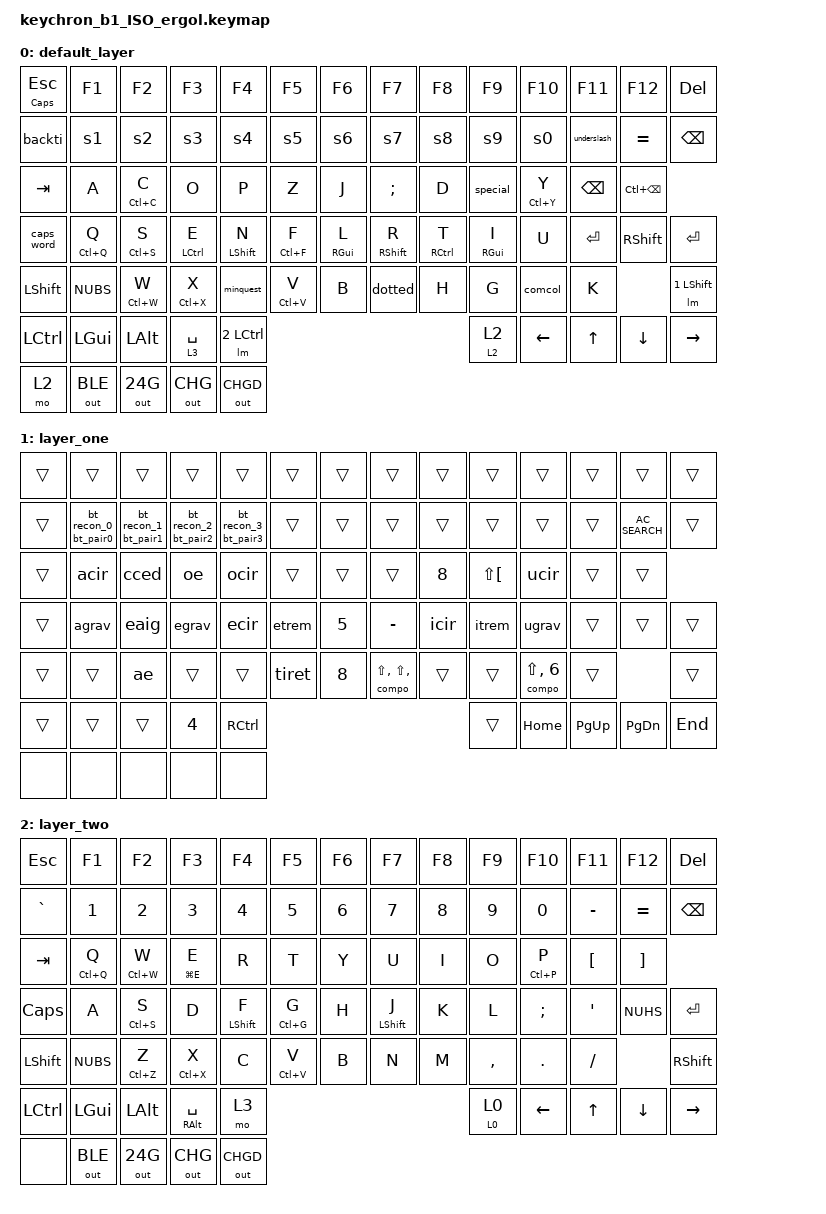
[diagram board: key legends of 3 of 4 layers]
/*
 * Copyright (c) 2023 The ZMK Contributors
 *
 * SPDX-License-Identifier: MIT
 */

#include <behaviors.dtsi>
#include <dt-bindings/zmk/keys.h>
#include <dt-bindings/zmk/rgb.h>
#include <dt-bindings/zmk/bt.h>
#include <dt-bindings/zmk/outputs.h>

&caps_word {
    continue-list = <UNDERSCORE MINUS BACKSPACE DELETE SEMI>;
};
&mt {
    tapping-term-ms = <300>;
    flavor = "tap-preferred";
};
&sl {
    release-after-ms = <5000>;
};

/ {
    ZMK_MACRO(recover, bindings = <&out OUT_RECOVER>;)
    ZMK_MACRO(change, bindings = <&out OUT_FN>;)
    ZMK_MACRO(fn_win, bindings = <&out OUT_FN_WIN>;)

    ZMK_MACRO(en_bootloader, bindings = <&bootloader>;)
    ZMK_MACRO1(MA,bindings=<&kp 0x770000>;)

    long_press_recover:l1 {
        compatible = "zmk,behavior-hold-tap";
        label = "l1";
        #binding-cells = <2>;
        flavor = "tap-preferred";
        tapping-term-ms = <3000>;  // delay amount in ms
        bindings = <&recover>, <&none>;
    };

    long_press_change:l2{
        compatible = "zmk,behavior-hold-tap";
        label = "lp_change";
        #binding-cells = <2>;
        flavor = "tap-preferred";
        tapping-term-ms = <3000>;  // delay amount in ms
        bindings = <&change>, <&none>;
    };
    long_press_bootloader:l3{
        compatible = "zmk,behavior-hold-tap";
        label = "lp_bootloader";
        #binding-cells = <2>;
        flavor = "tap-preferred";
        tapping-term-ms = <3000>;  // delay amount in ms
        bindings = <&en_bootloader>, <&none>;
    };
    long_press_fn_win:l4{
        compatible = "zmk,behavior-hold-tap";
        label = "lp_fn_win";
        #binding-cells = <2>;
        flavor = "tap-preferred";
        tapping-term-ms = <3000>;   
        bindings = <&fn_win>, <&none>;
    };
   

    combos1 {
        compatible = "zmk,combos";
        combo_jz {
            timeout-ms = <1000>;
            layers = <1 3>;
            key-positions = <48 57>; //fn+j+z
            bindings = <&long_press_recover 0 0>;
        };
        combo_xl {
            timeout-ms = <1000>;
            layers =< 1 3>;
            key-positions = <58 50>; //fn+x+l
            bindings = <&long_press_change 0 0>;
        };
        // combo_b {
        //     timeout-ms = <1000>;
        //     layers =< 1 3>;
        //     //slow-release = <true>;
        //     key-positions = <61>; //fn+b
        //     bindings = <&out OUT_BAT>;
        // };

        // combo_win_l {
        //     timeout-ms = <1000>;
        //     layers =< 1 3>;
        //     //slow-release = <true>;
        //     key-positions = <69>; //fn+win
        //     bindings = <&long_press_fn_win 0 0>;
        // };

        // combo_t0 {
        //     timeout-ms = <10 >;
        //     layers =<4>;
          
        //     key-positions = <80 90>;  
        //     bindings = <&to 3 >;
        // };
        // combo_t1 {
        //     timeout-ms = <10 >;
        //     layers =<4>;
          
        //     key-positions = <80 91>;  
        //     bindings = <&tog 3 >;
        // };
        // combo_t2 {
        //     timeout-ms = <10 >;
        //     layers =<4>;
          
        //     key-positions = <80 92>;  
        //     bindings = <&sl 3 >;
        // };
        // combo_t3 {
        //     timeout-ms = <10 >;
        //     layers =<4>;
          
        //     key-positions = <70 93>;  
        //     bindings = <&lt 3 SPACE>;
        // };
        // combo_t4 {
        //     timeout-ms = <10 >;
        //     layers =<4>;
          
        //     key-positions = <81 94>;  
        //     bindings = <&sk LSHIFT>;
        // };
        // combo_t5 {
        //     timeout-ms = <10 >;
        //     layers =<4>;
          
        //     key-positions = <81 93>;  
        //     bindings = <&mt LSHIFT SPACE>;
        // };
        // combo_t6 {
        //     timeout-ms = <10 >;
        //     layers =<4>;
          
        //     key-positions = <81 93>;  
        //     bindings = <&gresc>;
        // };
    };

    td0 {
        compatible = "zmk,behavior-tap-dance";
        label = "TAPD_LAYER";
        #binding-cells = <1>;
        tapping-term-ms = <350>;
        bindings =<&mo 0>,<&mo 0>,<&mo 0>,<&mo 0>,<&to 0>;
    };
    ZMK_MACRO(bt_pair0, bindings = <&bt BT_PAIR 0>;)
    ZMK_MACRO(bt_pair1, bindings = <&bt BT_PAIR 1>;)
    ZMK_MACRO(bt_pair2, bindings = <&bt BT_PAIR 2>;)
    ZMK_MACRO(bt_pair3, bindings = <&bt BT_PAIR 3>;)
    ZMK_MACRO(bt_recon_0, bindings = <&bt BT_SEL 0>;)
    ZMK_MACRO(bt_recon_1, bindings = <&bt BT_SEL 1>;)
    ZMK_MACRO(bt_recon_2, bindings = <&bt BT_SEL 2>;)
    ZMK_MACRO(bt_recon_3, bindings = <&bt BT_SEL 3>;)
    


    bt_pair_0: bt_pair_0 {
        compatible = "zmk,behavior-hold-tap";
        label = "bt_pair0";
        #binding-cells = <2>;
        flavor = "tap-preferred";
        tapping-term-ms = <3000>;  // delay amount in ms
        bindings = <&bt_pair0>, <&bt_recon_0>;
    };
    bt_pair_1: bt_pair_1 {
        compatible = "zmk,behavior-hold-tap";
        label = "bt_pair1";
        #binding-cells = <2>;
        flavor = "tap-preferred";
        tapping-term-ms = <3000>;  // delay amount in ms
        bindings = <&bt_pair1>, <&bt_recon_1>;
    };
    bt_pair_2: bt_pair_2 {
        compatible = "zmk,behavior-hold-tap";
        label = "bt_pair2";
        #binding-cells = <2>;
        flavor = "tap-preferred";
        tapping-term-ms = <3000>;  // delay amount in ms
        bindings = <&bt_pair2>, <&bt_recon_2>;
    };
    bt_pair_3: bt_pair_3 {
        compatible = "zmk,behavior-hold-tap";
        label = "bt_pair3";
        #binding-cells = <2>;
        flavor = "tap-preferred";
        tapping-term-ms = <3000>;  // delay amount in ms
        bindings = <&bt_pair3>, <&bt_recon_3>;
    };
    uc:user_custom {
        compatible = "zmk,behavior-key-press";
        label ="user_custom";
        #binding-cells =<1>;
    };

    // ----------------------ERGOL SPECIFICS----------------------------------
    
    behaviors {

    //LAYER 0
        minquest: minus_question {
            compatible = "zmk,behavior-mod-morph";
            #binding-cells = <0>;
            label = "- ?";
            bindings = <&kp N6>, <&kp M>;
            mods = <(MOD_LSFT|MOD_RSFT)>;
            keep-mods = <(MOD_LSFT|MOD_RSFT)>;
        };
        dotted: dot_column {
            compatible = "zmk,behavior-mod-morph";
            #binding-cells = <0>;
            label = ". :";
            bindings = <&kp LS(COMMA)>, <&kp DOT>;
            mods = <(MOD_LSFT|MOD_RSFT)>;
        };
        comcol: comma_column {
            compatible = "zmk,behavior-mod-morph";
            #binding-cells = <0>;
            label = ", ;";
            bindings = <&kp M>, <&kp COMMA>;
            mods = <(MOD_LSFT|MOD_RSFT)>;
        };
        quotted: quote_double {
            compatible = "zmk,behavior-mod-morph";
            #binding-cells = <0>;
            label = "none";
            bindings = <&kp N4>, <&kp N3>;
            mods = <(MOD_LSFT|MOD_RSFT)>;
        };
        backti: backquote_tilde {
            compatible = "zmk,behavior-mod-morph";
            #binding-cells = <0>;
            label = "tilde";
            bindings = <&kp RA(N7)>, <&kp RA(N2)>;
            mods = <(MOD_LSFT|MOD_RSFT)>;
        };
        underslash: underscore_slash {
            compatible = "zmk,behavior-mod-morph";
            #binding-cells = <0>;
            label = "slash";
            bindings = <&kp LS(DOT)>, <&kp N8>;
            mods = <(MOD_LSFT|MOD_RSFT)>;
        };
        special: special {
            compatible = "zmk,behavior-mod-morph";
            #binding-cells = <0>;
            label = "special";
            bindings = <&sl 1>, <&kp FSLH>;
            mods = <(MOD_LSFT|MOD_RSFT)>;
        };
        open: opening_brackets {
            compatible = "zmk,behavior-mod-morph";
            #binding-cells = <0>;
            label = "opening";
            bindings = <&kp RA(N5)>, <&kp RA(N4)>;
            mods = <(MOD_LSFT|MOD_RSFT)>;
        };        
        close: closing_brackets {
            compatible = "zmk,behavior-mod-morph";
            #binding-cells = <0>;
            label = "closing";
            bindings = <&kp RA(MINUS)>, <&kp RA(EQUAL)>;
            mods = <(MOD_LSFT|MOD_RSFT)>;
        };
        backpipe: backslash_pipe {
            compatible = "zmk,behavior-mod-morph";
            #binding-cells = <0>;
            label = "backpipe";
            bindings = <&kp RA(N8)>, <&kp RA(N6)>;
            mods = <(MOD_LSFT|MOD_RSFT)>;
        };

        s1: special1 {
            compatible = "zmk,behavior-mod-morph";
            #binding-cells = <0>;
            label = "1";
            bindings = <&kp LS(N1)>, <&kp RA(E)>;
            mods = <(MOD_LSFT|MOD_RSFT)>;
        };
        s2: special2 {
            compatible = "zmk,behavior-mod-morph";
            #binding-cells = <0>;
            label = "2";
            bindings = <&kp LS(N2)>, <&compo NUBS NUBS>;
            mods = <(MOD_LSFT|MOD_RSFT)>;
        };
        s3: special3 {
            compatible = "zmk,behavior-mod-morph";
            #binding-cells = <0>;
            label = "3";
            bindings = <&kp LS(N3)>, <&compo LS(NUBS) LS(NUBS)>;
            mods = <(MOD_LSFT|MOD_RSFT)>;
        };
        s4: special4 {
            compatible = "zmk,behavior-mod-morph";
            #binding-cells = <0>;
            label = "4";
            bindings = <&kp LS(N4)>, <&kp RBKT>;
            mods = <(MOD_LSFT|MOD_RSFT)>;
        };
        s5: special5 {
            compatible = "zmk,behavior-mod-morph";
            #binding-cells = <0>;
            label = "5";
            bindings = <&kp LS(N5)>, <&kp LS(SQT)>;
            mods = <(MOD_LSFT|MOD_RSFT)>;
        };
        s6: special6 {
            compatible = "zmk,behavior-mod-morph";
            #binding-cells = <0>;
            label = "6";
            bindings = <&kp LS(N6)>, <&kp LBKT>;
            mods = <(MOD_LSFT|MOD_RSFT)>;
        };     
        s7: special7 {
            compatible = "zmk,behavior-mod-morph";
            #binding-cells = <0>;
            label = "7";
            bindings = <&kp LS(N7)>, <&kp N1>;
            mods = <(MOD_LSFT|MOD_RSFT)>;
        };    
        s8: special8 {
            compatible = "zmk,behavior-mod-morph";
            #binding-cells = <0>;
            label = "8";
            bindings = <&kp LS(N8)>, <&kp NUHS>;
            mods = <(MOD_LSFT|MOD_RSFT)>;
        };            
        s9: special9 {
            compatible = "zmk,behavior-mod-morph";
            #binding-cells = <0>;
            label = "9";
            bindings = <&kp LS(N9)>, <&kp RA(N3)>;
            mods = <(MOD_LSFT|MOD_RSFT)>;
        }; 
        s0: special0 {
            compatible = "zmk,behavior-mod-morph";
            #binding-cells = <0>;
            label = "0";
            bindings = <&kp LS(N0)>, <&kp RA(N0)>;
            mods = <(MOD_LSFT|MOD_RSFT)>;
        };
        
    //LAYER1

        acir: circum_a {
            compatible = "zmk,behavior-mod-morph";
            #binding-cells = <0>;
            label = "â";
            bindings = <&dead LBKT Q>, <&dead LBKT LS(Q)>;
            mods = <(MOD_LSFT|MOD_RSFT)>;
        };

        cced: cedil_c {
            compatible = "zmk,behavior-mod-morph";
            #binding-cells = <0>;
            label = "ç";
            bindings = <&kp N9>, <&compo M LS(C)>;
            mods = <(MOD_LSFT|MOD_RSFT)>;
        };
        oe: oe {
            compatible = "zmk,behavior-mod-morph";
            #binding-cells = <0>;
            label = "œ";
            bindings = <&compo O E>, <&compo LS(O) LS(E)>;
            mods = <(MOD_LSFT|MOD_RSFT)>;
        };
        ocir: circum_o {
            compatible = "zmk,behavior-mod-morph";
            #binding-cells = <0>;
            label = "ô";
            bindings = <&dead LBKT O>, <&dead LBKT LS(O)>;
            mods = <(MOD_LSFT|MOD_RSFT)>;
        };
        ucir: circum_u {
            compatible = "zmk,behavior-mod-morph";
            #binding-cells = <0>;
            label = "û";
            bindings = <&dead LBKT U>, <&dead LBKT LS(U)>;
            mods = <(MOD_LSFT|MOD_RSFT)>;
        };
        agrav: grav_a {
            compatible = "zmk,behavior-mod-morph";
            #binding-cells = <0>;
            label = "à";
            bindings = <&kp N0>, <&compo LS(Q) RA(N7)>;
            mods = <(MOD_LSFT|MOD_RSFT)>;
        };
        eaig: aig_e {
            compatible = "zmk,behavior-mod-morph";
            #binding-cells = <0>;
            label = "é";
            bindings = <&kp N2>, <&compo LS(E) N4>;
            mods = <(MOD_LSFT|MOD_RSFT)>;
        };

        egrav: grav_e {
            compatible = "zmk,behavior-mod-morph";
            #binding-cells = <0>;
            label = "è";
            bindings = <&kp N7>, <&compo LS(E) RA(N7)>;
            mods = <(MOD_LSFT|MOD_RSFT)>;
        };
        ecir: circum_e {
            compatible = "zmk,behavior-mod-morph";
            #binding-cells = <0>;
            label = "ê";
            bindings = <&dead LBKT E>, <&dead LBKT LS(E)>;
            mods = <(MOD_LSFT|MOD_RSFT)>;
        };
        etrem: trema_e {
            compatible = "zmk,behavior-mod-morph";
            #binding-cells = <0>;
            label = "ë";
            bindings = <&dead LS(LBKT) E>, <&dead LS(LBKT) LS(E)>;
            mods = <(MOD_LSFT|MOD_RSFT)>;
        };

        icir: circum_i {
            compatible = "zmk,behavior-mod-morph";
            #binding-cells = <0>;
            label = "î";
            bindings = <&dead LBKT I>, <&dead LBKT LS(I)>;
            mods = <(MOD_LSFT|MOD_RSFT)>;
        };
        itrem: trema_i {
            compatible = "zmk,behavior-mod-morph";
            #binding-cells = <0>;
            label = "ï";
            bindings = <&dead LS(LBKT) I>, <&dead LS(LBKT) LS(I)>;
            mods = <(MOD_LSFT|MOD_RSFT)>;
        };

        ugrav: grav_u {
            compatible = "zmk,behavior-mod-morph";
            #binding-cells = <0>;
            label = "ù";
            bindings = <&kp SQT>, <&compo LS(U) RA(N7)>;
            mods = <(MOD_LSFT|MOD_RSFT)>;
        };
        ae: ae {
            compatible = "zmk,behavior-mod-morph";
            #binding-cells = <0>;
            label = "æ";
            bindings = <&compo Q E>, <&compo LS(Q) LS(E)>;
            mods = <(MOD_LSFT|MOD_RSFT)>;
        };


        // LAYERS 
        mo_tog: behavior_mo_tog {
            compatible = "zmk,behavior-hold-tap";
            #binding-cells = <2>;
            label = "motog";
            flavor = "hold-preferred";
            tapping-term-ms = <200>;
            bindings = <&mo>, <&tog>;
        };
};

    macros {


    lm: lm {
    compatible = "zmk,behavior-macro-two-param";
    label = "some";
    wait-ms = <0>;
    tap-ms = <0>;
    #binding-cells = <2>;
    bindings
        = <&macro_param_1to1>
        , <&macro_press &mo MACRO_PLACEHOLDER>
        , <&macro_param_2to1>
        , <&macro_press &kp MACRO_PLACEHOLDER>
        , <&macro_pause_for_release>
        , <&macro_param_2to1>
        , <&macro_release &kp MACRO_PLACEHOLDER>
        , <&macro_param_1to1>
        , <&macro_release &mo MACRO_PLACEHOLDER>
        ;
};
        tiret: tiret_long {
            compatible = "zmk,behavior-macro";
            #binding-cells = <0>;
            label = "—";
            bindings = <&macro_tap &kp SCROLLLOCK &kp N6 &kp N6 &kp N6>;
            
        };

        compo: compose {            
            compatible = "zmk,behavior-macro-two-param";
            label = "COMPOSE";
            wait-ms = <40>;
            #binding-cells = <2>; // Must be 2
            bindings = <&macro_tap &kp SCROLLLOCK>
                    , <&macro_param_1to1>
                    , <&macro_tap &kp MACRO_PLACEHOLDER>
                    , <&macro_param_2to1>
                    , <&macro_tap &kp MACRO_PLACEHOLDER>
                    ;
        };

        dead: dead {            
            compatible = "zmk,behavior-macro-two-param";
            label = "dead";
            wait-ms = <30>;
            #binding-cells = <2>; // Must be 2
            bindings = <&macro_param_1to1>
                    , <&macro_tap &kp MACRO_PLACEHOLDER>
                    , <&macro_param_2to1>
                    , <&macro_tap &kp MACRO_PLACEHOLDER>
                    ;
        };


    };

    //TODO
    // caps word et le M qui ne majuscule pas --- 
    // upper and lower chiffre en layer 1

    // shift space for tab
    // del plus proche
    // flèches plus proches
    // ctrl space for backspace
    // backspace for whole word
    // usage de alt (gr)  our RSHIFT pour enter
    // utility layer en layer 2 éventuellement ou mieux incorporer le layer 2 dans le flux


	keymap {
    	compatible = "zmk,keymap";
            //mac
        default_layer {
        bindings = <
          //ESC         //f1                    //f2                //f3                                    //f4                //f5                //f6            //f7            //f8                //f9        //f10       //f11               //f12               //DEL                                              
        //&kp ESC     &kp C_BRIGHTNESS_DEC    &kp C_BRIGHTNESS_INC    &kp C_AC_DESKTOP_SHOW_ALL_WINDOWS   &kp  C_AC_MAC_LAUNCH    &kp C_AC_SEARCH     &kp C_AL_LOCK   &kp C_PREVIOUS  &kp C_PLAY_PAUSE    &kp C_NEXT  &kp C_MUTE  &kp C_VOLUME_DOWN   &kp C_VOLUME_UP     &kp DEL  
        &mt CLCK ESC     &kp F1                  &kp F2                  &kp F3                        &kp F4                  &kp F5              &kp F6          &kp F7          &kp F8              &kp F9      &kp F10           &kp F11             &kp F12              &kp DEL  
        &backti     &s1                     &s2                     &s3                           &s4                     &s5                 &s6             &s7             &s8                 &s9         &s0               &underslash         &kp EQUAL           &kp BSPC 
        &kp TAB     &kp A                   &mt LC(C) C             &kp O                         &kp P                   &kp Z               &kp J           &kp SEMI        &kp D               &special    &mt LC(Y) Y       &kp BSPC               &kp LC(BSPC)            
        &caps_word  &mt LC(Q) Q             &mt LC(S) S             &mt LCTRL E                   &mt LSHFT N             &mt LC(F) F         &mt RGUI L           &mt RSHFT R    &mt RCTRL T         &mt RGUI I       &kp U             &kp RET            &kp RSHFT            &kp RET 
        &kp LSHFT   &kp NUBS                &mt LC(W) W             &mt LC(X) X                   &minquest               &mt LC(V) V         &kp B           &dotted         &kp H               &kp G       &comcol           &kp K                                &lm 1 LSHFT
        &kp LCTRL   &kp LGUI                &kp LALT                          &lt 3 SPACE                                                                                              &lm 2 LCTRL            &mo_tog 2 2       &kp LEFT    &kp UP              &kp DOWN            &kp RIGHT   
        &mo 2       &out OUT_BLE            &out OUT_24G            &out OUT_CHG                        &out OUT_CHGD 
            >;
        };
        //mac
        layer_one  {
        bindings = < 
        //&trans      &kp F1                  &kp F2                  &kp F3                              &kp F4                  &kp F5              &kp F6                        &kp F7          &kp F8              &kp F9                  &kp F10     &kp F11             &kp F12             &trans    
        &trans      &trans                  &trans                  &trans                              &trans                  &trans              &trans                          &trans                  &trans             &trans                   &trans      &trans              &trans              &trans
        &trans      &bt_pair_0 0 0          &bt_pair_1 0 0          &bt_pair_2 0 0                      &bt_pair_3 0 0          &trans              &trans                          &trans                  &trans              &trans                  &trans      &trans              &kp C_AC_SEARCH     &trans      
        &trans      &acir                   &cced                   &oe                                 &ocir                   &trans              &trans                          &trans                  &kp N8             &kp LS(LBKT)             &ucir      &trans              &trans              
        &trans      &agrav                  &eaig                   &egrav                              &ecir                   &etrem                &kp N5                         &kp MINUS               &icir              &itrem                   &ugrav     &trans              &trans              &trans
        &trans      &trans                  &ae                     &trans                              &trans                  &tiret              &kp N8               &compo LS(COMMA) LS(COMMA)          &trans              &trans      &compo LS(COMMA) N6   &trans                                  &trans
        &trans      &trans                  &trans                         &kp N4                                                                                                                       &kp RCTRL           &trans                  &kp HOME   &kp PG_UP   &kp PG_DN    &kp END  
        //
        &none       &none                   &none                   &none                               &none
            >;
        };
        //win
        layer_two {
 		bindings = <
        &kp ESC 	&kp F1 	               &kp F2 	                &kp F3 	                            &kp F4 	                &kp F5 	            &kp F6 	        &kp F7 	        &kp F8 	            &kp F9 	     &kp F10 	&kp F11 	         &kp F12 	         &kp DEL     
        &kp GRAVE	&kp N1 	               &kp N2 	                &kp N3 	                            &kp N4 	                &kp N5 	            &kp N6 	        &kp N7 	        &kp N8 	            &kp N9 	     &kp N0     &kp MINUS 	         &kp EQUAL 	         &kp BSPC
        &kp TAB 	&mt LC(Q) Q            &mt LC(W) W              &mt LG(E) E                         &kp R 	                &kp T               &kp Y 	        &kp U 	        &kp I 	            &kp O 	     &mt LC(P) P	&kp LBKT 	         &kp RBKT 	         
        &kp CLCK 	&kp A 	               &mt LC(S) S 	            &kp D 	                            &mt LSHFT F             &mt LC(G) G         &kp H 	        &mt LSHFT J 	    &kp K 	            &kp L 	     &kp SEMI 	&kp SQT              &kp NUHS            &kp RET
        &kp LSHFT   &kp NUBS               &mt LC(Z) Z 	            &mt LC(X) X                         &kp C 	                &mt LC(V) V         &kp B 	        &kp N 	        &kp M 	            &kp COMMA    &kp DOT    &kp FSLH                                 &kp RSHFT
        &kp LCTRL 	&kp LGUI               &kp LALT                      &mt RALT SPACE                		                                                                            &mo 3   	        &mo_tog 0 0		  &kp LEFT 	 &kp UP      &kp DOWN 	&kp RIGHT 	
        //
        &none       &out OUT_BLE           &out OUT_24G             &out OUT_CHG                        &out OUT_CHGD 
            >;
        };
        //win
        layer_three {
        bindings = < 
                    //f1                    //f2                    //f3                                //f4                        //f5            //f6              //f7            //f8              //f9        //f10           //f11                         //f12          
        &kp PSCRN  &kp C_BRIGHTNESS_DEC    &kp C_BRIGHTNESS_INC        &uc LG(TAB)                         &uc LG(E)               &kp C_AC_SEARCH     &uc LG(L)       &kp C_PREVIOUS  &kp C_PLAY_PAUSE    &kp C_NEXT  &kp C_MUTE  &kp C_VOLUME_DOWN            &kp C_VOLUME_UP     &trans
        &trans  &bt_pair_0 0 0          &bt_pair_1 0 0              &bt_pair_2 0 0                      &bt_pair_3 0 0          &trans              &trans          &trans          &trans              &trans      &trans      &long_press_bootloader          &trans           &trans &trans &trans 
        &trans  &kp LBKT                &kp NUBS                    &kp LS(NUBS)                        &kp RBKT                &kp LS(SQT)         &kp RA(N0)      &kp N1          &kp NUHS            &kp N4      &kp RA(N7)  &trans                          &trans              
        &trans  &kp RA(N4)              &kp N5                      &kp MINUS                           &kp RA(EQUAL)           &kp EQUAL           &kp RA(N8)      &kp LS(EQUAL)   &kp N6              &kp LS(DOT) &kp N3      &trans                          &trans                  &trans 
        &trans  &trans                  &kp RA(N2)                  &kp RA(N5)                          &kp RA(MINUS)           &kp N8              &kp RA(N3)      &kp RA(N6)      &kp FSLH            &kp COMMA   &kp DOT     &kp LS(M)                                           &uc LG(DOT) 
        &trans  &trans                  &trans                           &trans                                                                                                     &kp RCTRL           &trans      &kp HOME    &kp PG_UP    &kp PG_DN   &kp END    
        //
        &none   &none                   &none                       &none                               &none
            >;
        };
   
   
	};
};
